# f280015x_dcsm_common_regs register map
Vendor: Texas Instruments
Peripheral module from a debugger description file (folder C2000).
Address unit: 16 bits
Registers are 32-bit, read-write, no defined reset value unless marked. A register's access mark holds for its fields unless they carry their own. Offsets are as the file gives them; lines under a group give offsets from that group; [hi:lo] are bit positions; {n}, {i} and the like mark numbered series; 'fields as' and 'values as' point back to an identical list; <NAME> marks a mode.

## DCSM_COMMON_REGS — DCSM COMMON Registers
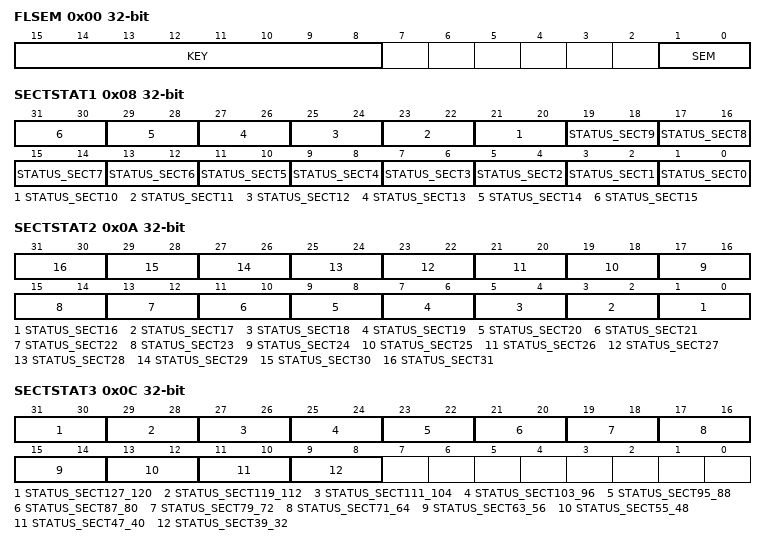
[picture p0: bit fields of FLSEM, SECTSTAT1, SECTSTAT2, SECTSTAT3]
0x00 FLSEM — Flash Wrapper Semaphore Register
  [15:8] KEY — Semaphore Key
  [1:0] SEM — Flash Semaphore Bit
0x08 SECTSTAT1 ro — Flash Sectors Status Register 1
  [2n+1:2n] STATUS_SECT{n} (n=0..15) — Zone Status Flash Bank 0 Sector {n}
0x0A SECTSTAT2 ro — Flash Sectors Status Register 2
  [2n-31:2n-32] STATUS_SECT{n} (n=16..31) — Zone Status Flash Bank 0 Sector {n}
0x0C SECTSTAT3 ro — Flash Sectors Status Register 3
  [31:30] STATUS_SECT127_120 — Zone Status flash Bank 0 Sectors 127-120
  [29:28] STATUS_SECT119_112 — Zone Status flash Bank 0 Sectors 119-112
  [27:26] STATUS_SECT111_104 — Zone Status flash Bank 0 Sectors 111-104
  [25:24] STATUS_SECT103_96 — Zone Status flash Bank 0 Sectors 103-96
  [23:22] STATUS_SECT95_88 — Zone Status flash Bank 0 Sectors 95-88
  [21:20] STATUS_SECT87_80 — Zone Status flash Bank 0 Sectors 87-80
  [19:18] STATUS_SECT79_72 — Zone Status flash Bank 0 Sectors 79-72
  [17:16] STATUS_SECT71_64 — Zone Status flash Bank 0 Sectors 71-64
  [15:14] STATUS_SECT63_56 — Zone Status flash Bank 0 Sectors 63-56
  [13:12] STATUS_SECT55_48 — Zone Status flash Bank 0 Sectors 55-48
  [11:10] STATUS_SECT47_40 — Zone Status flash Bank 0 Sectors 47-40
  [9:8] STATUS_SECT39_32 — Zone Status flash Bank 0 Sectors 39-32
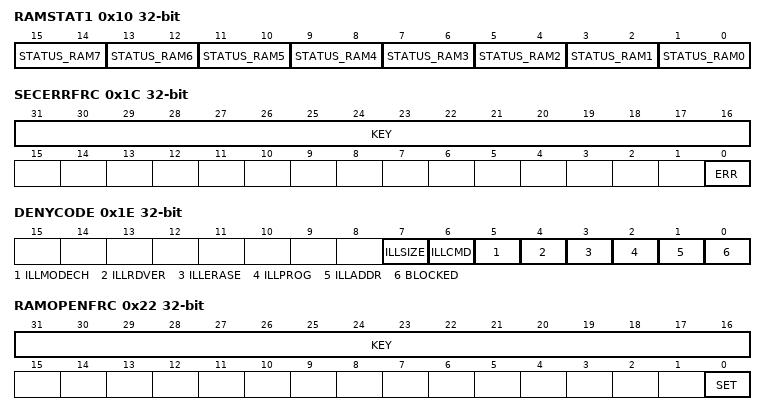
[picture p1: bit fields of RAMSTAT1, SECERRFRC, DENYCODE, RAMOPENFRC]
0x10 RAMSTAT1 ro — RAM Status Register 1
  [15:14] STATUS_RAM7 — Zone Status RAM LS1 Section D
  [13:12] STATUS_RAM6 — Zone Status RAM LS1 Section C
  [11:10] STATUS_RAM5 — Zone Status RAM LS1 Section B
  [9:8] STATUS_RAM4 — Zone Status RAM LS1 Section A
  [7:6] STATUS_RAM3 — Zone Status RAM LS0 Section D
  [5:4] STATUS_RAM2 — Zone Status RAM LS0 Section C
  [3:2] STATUS_RAM1 — Zone Status RAM LS0 Section B
  [1:0] STATUS_RAM0 — Zone Status RAM LS0 Section A
0x18 SECERRSTAT ro — Security Error Status Register
  [0] ERR — Security Configuration load Error Status
0x1A SECERRCLR — Security Error Clear Register
  [0] ERR — Clear Security Configuration Load Error Status Bit
0x1C SECERRFRC — Security Error Force Register
  [31:16] KEY — Valid Register Write Key
  [0] ERR — Set Security Configuration Load Error Status Bit
0x1E DENYCODE ro — Flash Authorization Denial Code
  [7] ILLSIZE — Illegal Command Size
  [6] ILLCMD — Illegal Command
  [5] ILLMODECH — Illegal Mode Change
  [4] ILLRDVER — Illegal Read Verify Address
  [3] ILLERASE — Illegal Erase Address
  [2] ILLPROG — Illegal Program Address
  [1] ILLADDR — Illegal Address Code
  [0] BLOCKED — Blocked Code
0x20 RAMOPENSTAT ro — RAM Security Open Status Register
  [0] RAMOPEN — RAM Security Open
0x22 RAMOPENFRC — RAM Security Open Force Register
  [31:16] KEY — Valid Write KEY
  [0] SET — Set RAM Open request
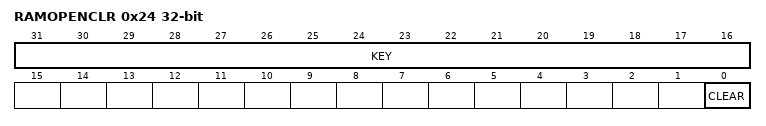
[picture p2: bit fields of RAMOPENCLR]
0x24 RAMOPENCLR — RAM Security Open Clear Register
  [31:16] KEY — Valid Write KEY
  [0] CLEAR — Clear RAM Open request
0x26 RAMOPENLOCK
  [0] LOCK — RAMOPEN Lock
0x28 UID_UNIQUE_31_0 — Unique Identification Number Low
  [31:0] UID_L
0x2A UID_UNIQUE_63_32 — Unique Identification Number High
  [31:0] UID_H
0x2C PARTIDH — Part Identification High Register
  [31:0] ID — High Part Identification Number
